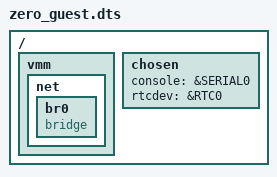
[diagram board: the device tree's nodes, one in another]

/dts-v1/;

/include/ "vexpress-a15.dtsi"

/ {
	vmm {
		net {
			br0 {
				device_type = "netswitch";
				compatible = "bridge";
			};
		};
	};

	chosen {
		console = &SERIAL0;
		rtcdev = &RTC0;
	};
};
